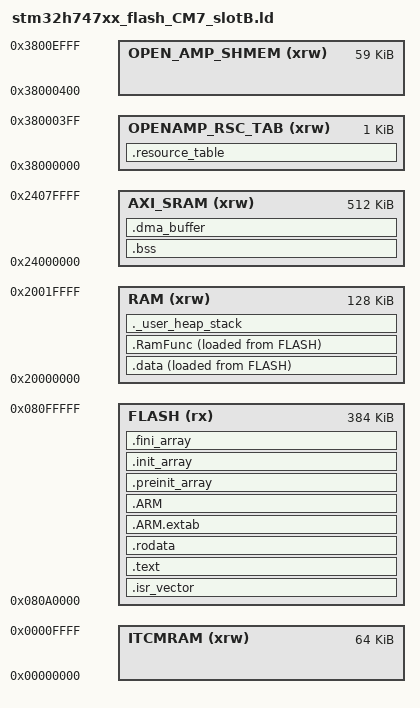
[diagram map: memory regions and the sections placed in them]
/*
******************************************************************************
**

**  File        : LinkerScript.ld
**
**
**                Slot B: 384K @ 0x080A0000 (OTA inactive / alternate run slot)
**
**  Abstract    : Linker script for STM32H7 series
**                APP Slot B under Bootloader (CM7)
**
*****************************************************************************
*/

/* Entry Point */
ENTRY(Reset_Handler)

/* Highest address of the user mode stack */
_estack = 0x20020000;    /* end of RAM */
/* Generate a link error if heap and stack don't fit into RAM */
_Min_Heap_Size = 0x200;      /* required amount of heap  */
_Min_Stack_Size = 0x2000; /* required amount of stack */

/* Specify the memory areas */
MEMORY
{
FLASH (rx)      : ORIGIN = 0x080A0000, LENGTH = 384K
RAM (xrw)      : ORIGIN = 0x20000000, LENGTH = 128K
AXI_SRAM (xrw) : ORIGIN = 0x24000000, LENGTH = 512K
ITCMRAM (xrw)      : ORIGIN = 0x00000000, LENGTH = 64K
OPENAMP_RSC_TAB (xrw) : ORIGIN = 0x38000000, LENGTH = 1K
OPEN_AMP_SHMEM (xrw) : ORIGIN = 0x38000400, LENGTH = 59K
}

__OPENAMP_region_start__ = ORIGIN(OPEN_AMP_SHMEM);
__OPENAMP_region_end__ = ORIGIN(OPEN_AMP_SHMEM) + LENGTH(OPEN_AMP_SHMEM);

/* Define output sections */
SECTIONS
{
  .isr_vector :
  {
    . = ALIGN(4);
    KEEP(*(.isr_vector))
    . = ALIGN(4);
  } >FLASH

  .text :
  {
    . = ALIGN(4);
    *(.text)
    *(.text*)
    *(.glue_7)
    *(.glue_7t)
    *(.eh_frame)

    KEEP (*(.init))
    KEEP (*(.fini))

    . = ALIGN(4);
    _etext = .;
  } >FLASH

  .rodata :
  {
    . = ALIGN(4);
    *(.rodata)
    *(.rodata*)
    . = ALIGN(4);
  } >FLASH

  .ARM.extab (READONLY) :
  {
    *(.ARM.extab* .gnu.linkonce.armextab.*)
  } >FLASH
  .ARM (READONLY) :
  {
    __exidx_start = .;
    *(.ARM.exidx*)
    __exidx_end = .;
  } >FLASH

  .preinit_array (READONLY) :
  {
    PROVIDE_HIDDEN (__preinit_array_start = .);
    KEEP (*(.preinit_array*))
    PROVIDE_HIDDEN (__preinit_array_end = .);
  } >FLASH
  .init_array (READONLY) :
  {
    PROVIDE_HIDDEN (__init_array_start = .);
    KEEP (*(SORT(.init_array.*)))
    KEEP (*(.init_array*))
    PROVIDE_HIDDEN (__init_array_end = .);
  } >FLASH
  .fini_array (READONLY) :
  {
    PROVIDE_HIDDEN (__fini_array_start = .);
    KEEP (*(SORT(.fini_array.*)))
    KEEP (*(.fini_array*))
    PROVIDE_HIDDEN (__fini_array_end = .);
  } >FLASH

  .resource_table (NOLOAD) :
  {
    . = ALIGN(4);
    KEEP(*(.resource_table))
    . = ALIGN(4);
  } >OPENAMP_RSC_TAB

  _sidata = LOADADDR(.data);

  .data :
  {
    . = ALIGN(4);
    _sdata = .;
    *(.data)
    *(.data*)

    . = ALIGN(4);
    _edata = .;
  } >RAM AT> FLASH

  .RamFunc :
  {
    . = ALIGN(4);
    _sramfunc = .;
    *(.RamFunc)
    *(.RamFunc*)
    _eramfunc = .;
    . = ALIGN(4);
  } >RAM AT> FLASH

  _sramfunc_init = LOADADDR(.RamFunc);

  . = ALIGN(4);
  .bss :
  {
    _sbss = .;
    __bss_start__ = _sbss;
    *(.bss)
    *(.bss*)
    *(COMMON)

    . = ALIGN(4);
    _ebss = .;
    __bss_end__ = _ebss;
  } >AXI_SRAM

  .dma_buffer (NOLOAD) :
  {
    . = ALIGN(32);
    *(.dma_buffer)
    *(.dma_buffer*)
    . = ALIGN(32);
  } >AXI_SRAM

  ._user_heap_stack :
  {
    . = ALIGN(8);
    PROVIDE ( end = . );
    PROVIDE ( _end = . );
    . = . + _Min_Heap_Size;
    . = . + _Min_Stack_Size;
    . = ALIGN(8);
  } >RAM

  /DISCARD/ :
  {
    libc.a ( * )
    libm.a ( * )
    libgcc.a ( * )
  }

  .ARM.attributes 0 : { *(.ARM.attributes) }
}
